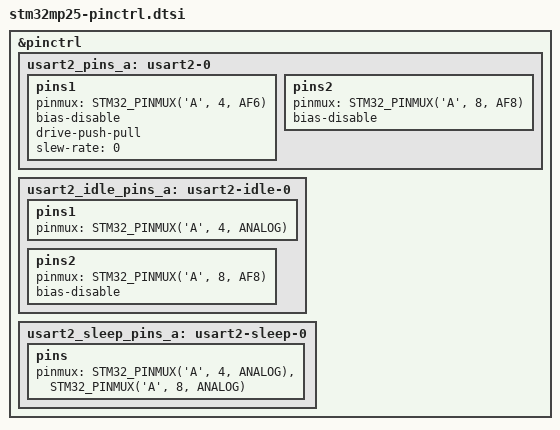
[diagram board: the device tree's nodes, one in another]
#include <dt-bindings/pinctrl/stm32-pinfunc.h>
&pinctrl {
	usart2_pins_a: usart2-0 {
		pins1 {
			pinmux = <STM32_PINMUX('A', 4, AF6)>;  
			bias-disable;
			drive-push-pull;
			slew-rate = <0>;
		};
		pins2 {
			pinmux = <STM32_PINMUX('A', 8, AF8)>;  
			bias-disable;
		};
	};
	usart2_idle_pins_a: usart2-idle-0 {
		pins1 {
			pinmux = <STM32_PINMUX('A', 4, ANALOG)>;  
		};
		pins2 {
			pinmux = <STM32_PINMUX('A', 8, AF8)>;  
			bias-disable;
		};
	};
	usart2_sleep_pins_a: usart2-sleep-0 {
		pins {
			pinmux = <STM32_PINMUX('A', 4, ANALOG)>,  
				 <STM32_PINMUX('A', 8, ANALOG)>;  
		};
	};
};
